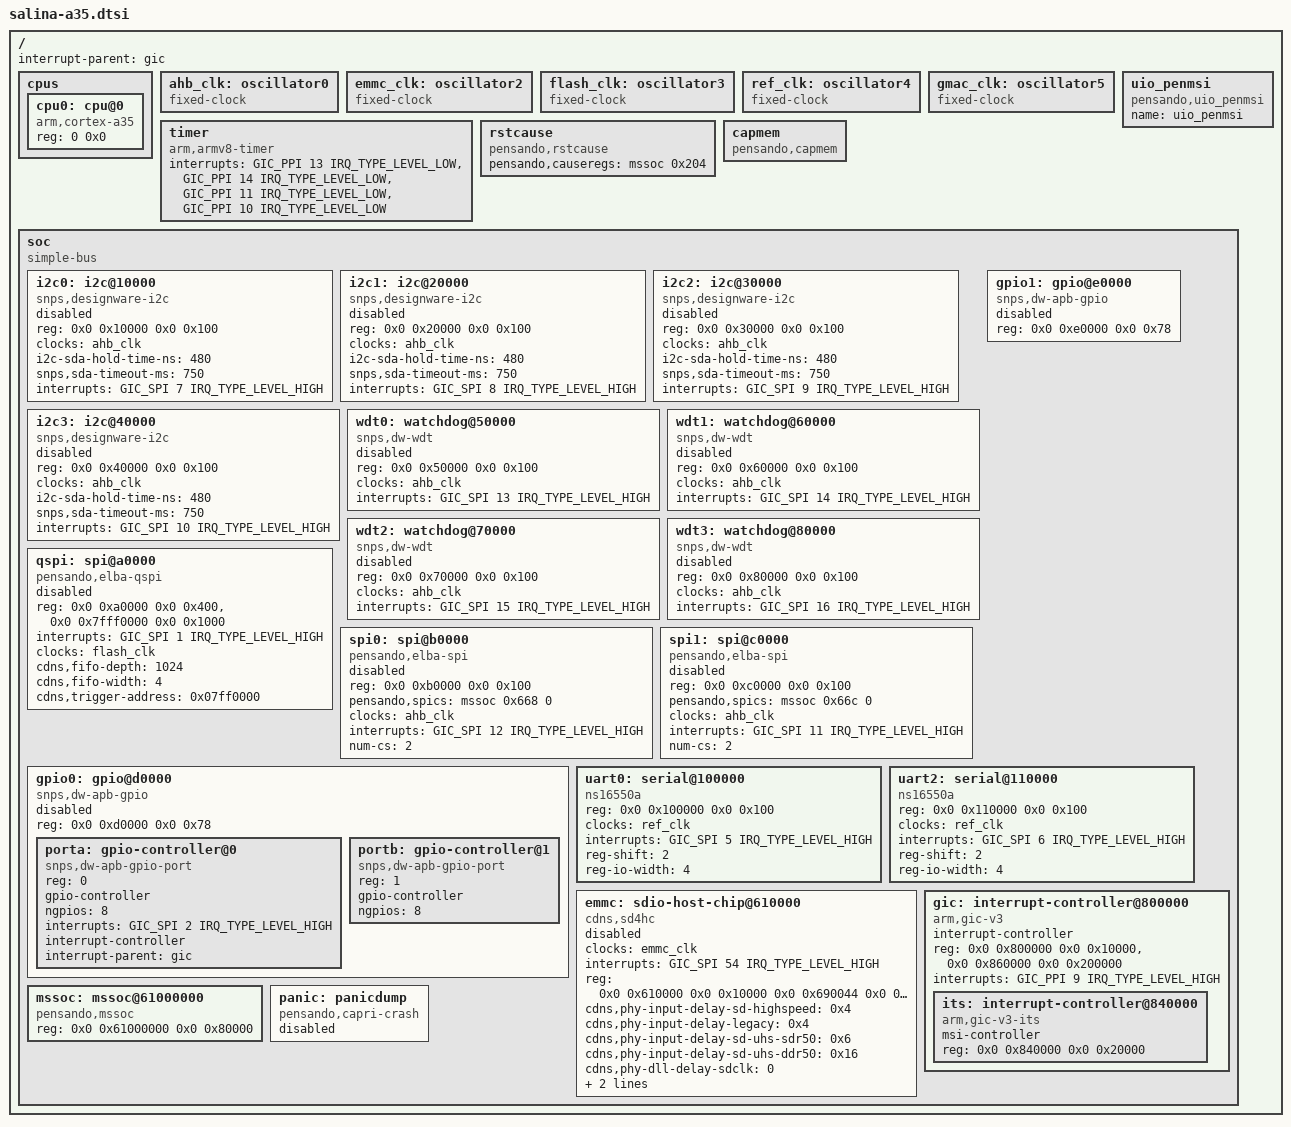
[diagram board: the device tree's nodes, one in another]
// SPDX-License-Identifier: (GPL-2.0-only or BSD-2-Clause)
/*
 * Copyright 2023-2024 Advanced Micro Devices, Inc.
 */

#include <dt-bindings/gpio/gpio.h>
#include "dt-bindings/interrupt-controller/arm-gic.h"
#include "dt-bindings/interrupt-controller/irq.h"

/ {
	interrupt-parent = <&gic>;
	#address-cells = <2>;
	#size-cells = <2>;

	cpus {
		#address-cells = <2>;
		#size-cells = <0>;

		cpu0: cpu@0 {
			device_type = "cpu";
			compatible = "arm,cortex-a35";
			reg = <0 0x0>;
		};
	};

	ahb_clk: oscillator0 {
		compatible = "fixed-clock";
		#clock-cells = <0>;
	};

	emmc_clk: oscillator2 {
		compatible = "fixed-clock";
		#clock-cells = <0>;
	};

	flash_clk: oscillator3 {
		compatible = "fixed-clock";
		#clock-cells = <0>;
	};

	ref_clk: oscillator4 {
		compatible = "fixed-clock";
		#clock-cells = <0>;
	};

	gmac_clk: oscillator5 {
		compatible = "fixed-clock";
		#clock-cells = <0>;
	};

	timer {
		compatible = "arm,armv8-timer";
		interrupts = <GIC_PPI 13 IRQ_TYPE_LEVEL_LOW>,
			     <GIC_PPI 14 IRQ_TYPE_LEVEL_LOW>,
			     <GIC_PPI 11 IRQ_TYPE_LEVEL_LOW>,
			     <GIC_PPI 10 IRQ_TYPE_LEVEL_LOW>;
	};

	/* Common UIO device for MSI drivers */
	uio_penmsi {
		compatible = "pensando,uio_penmsi";
		name = "uio_penmsi";
	};

	rstcause {
		compatible = "pensando,rstcause";
		pensando,causeregs = <&mssoc 0x204>;
	};

	capmem {
		compatible = "pensando,capmem";
	};

	soc: soc {
		compatible = "simple-bus";
		#address-cells = <2>;
		#size-cells = <2>;
		ranges;

		i2c0: i2c@10000 {
			compatible = "snps,designware-i2c";
			reg = <0x0 0x10000 0x0 0x100>;
			clocks = <&ahb_clk>;
			#address-cells = <1>;
			#size-cells = <0>;
			i2c-sda-hold-time-ns = <480>;
			snps,sda-timeout-ms = <750>;
			interrupts = <GIC_SPI 7 IRQ_TYPE_LEVEL_HIGH>;
			status = "disabled";
		};

		i2c1: i2c@20000 {
			compatible = "snps,designware-i2c";
			reg = <0x0 0x20000 0x0 0x100>;
			clocks = <&ahb_clk>;
			#address-cells = <1>;
			#size-cells = <0>;
			i2c-sda-hold-time-ns = <480>;
			snps,sda-timeout-ms = <750>;
			interrupts = <GIC_SPI 8 IRQ_TYPE_LEVEL_HIGH>;
			status = "disabled";
		};

		i2c2: i2c@30000 {
			compatible = "snps,designware-i2c";
			reg = <0x0 0x30000 0x0 0x100>;
			clocks = <&ahb_clk>;
			#address-cells = <1>;
			#size-cells = <0>;
			i2c-sda-hold-time-ns = <480>;
			snps,sda-timeout-ms = <750>;
			interrupts = <GIC_SPI 9 IRQ_TYPE_LEVEL_HIGH>;
			status = "disabled";
		};

		i2c3: i2c@40000 {
			compatible = "snps,designware-i2c";
			reg = <0x0 0x40000 0x0 0x100>;
			clocks = <&ahb_clk>;
			#address-cells = <1>;
			#size-cells = <0>;
			i2c-sda-hold-time-ns = <480>;
			snps,sda-timeout-ms = <750>;
			interrupts = <GIC_SPI 10 IRQ_TYPE_LEVEL_HIGH>;
			status = "disabled";
		};

		wdt0: watchdog@50000 {
			compatible = "snps,dw-wdt";
			reg = <0x0 0x50000 0x0 0x100>;
			clocks = <&ahb_clk>;
			interrupts = <GIC_SPI 13 IRQ_TYPE_LEVEL_HIGH>;
			status = "disabled";
		};

		wdt1: watchdog@60000 {
			compatible = "snps,dw-wdt";
			reg = <0x0 0x60000 0x0 0x100>;
			clocks = <&ahb_clk>;
			interrupts = <GIC_SPI 14 IRQ_TYPE_LEVEL_HIGH>;
			status = "disabled";
		};

		wdt2: watchdog@70000 {
			compatible = "snps,dw-wdt";
			reg = <0x0 0x70000 0x0 0x100>;
			clocks = <&ahb_clk>;
			interrupts = <GIC_SPI 15 IRQ_TYPE_LEVEL_HIGH>;
			status = "disabled";
		};

		wdt3: watchdog@80000 {
			compatible = "snps,dw-wdt";
			reg = <0x0 0x80000 0x0 0x100>;
			clocks = <&ahb_clk>;
			interrupts = <GIC_SPI 16 IRQ_TYPE_LEVEL_HIGH>;
			status = "disabled";
		};

		qspi: spi@a0000 {
			compatible = "pensando,elba-qspi";
			#address-cells = <1>;
			#size-cells = <0>;
			reg = <0x0 0xa0000 0x0 0x400>,
			      <0x0 0x7fff0000 0x0 0x1000>;
			interrupts = <GIC_SPI 1 IRQ_TYPE_LEVEL_HIGH>;
			clocks = <&flash_clk>;
			cdns,fifo-depth = <1024>;
			cdns,fifo-width = <4>;
			cdns,trigger-address = <0x07ff0000>;
			status = "disabled";
		};

		spi0: spi@b0000 {
			compatible = "pensando,elba-spi";
			reg = <0x0 0xb0000 0x0 0x100>;
			pensando,spics = <&mssoc 0x668 0>;
			clocks = <&ahb_clk>;
			interrupts = <GIC_SPI 12 IRQ_TYPE_LEVEL_HIGH>;
			#address-cells = <1>;
			#size-cells = <0>;
			num-cs = <2>;
			status = "disabled";
		};

		spi1: spi@c0000 {
			compatible = "pensando,elba-spi";
			reg = <0x0 0xc0000 0x0 0x100>;
			pensando,spics = <&mssoc 0x66c 0>;
			clocks = <&ahb_clk>;
			interrupts = <GIC_SPI 11 IRQ_TYPE_LEVEL_HIGH>;
			#address-cells = <1>;
			#size-cells = <0>;
			num-cs = <2>;
			status = "disabled";
		};

		gpio0: gpio@d0000 {
			#address-cells = <1>;
			#size-cells = <0>;
			compatible = "snps,dw-apb-gpio";
			reg = <0x0 0xd0000 0x0 0x78>;
			status = "disabled";

			porta: gpio-controller@0 {
				compatible = "snps,dw-apb-gpio-port";
				reg = <0>;
				gpio-controller;
				#gpio-cells = <2>;
				ngpios = <8>;
				interrupts = <GIC_SPI 2 IRQ_TYPE_LEVEL_HIGH>;
				interrupt-controller;
				interrupt-parent = <&gic>;
				#interrupt-cells = <2>;
			};
			portb: gpio-controller@1 {
				compatible = "snps,dw-apb-gpio-port";
				reg = <1>;
				gpio-controller;
				#gpio-cells = <2>;
				ngpios = <8>;
			};
		};

		gpio1: gpio@e0000 {
			#address-cells = <1>;
			#size-cells = <0>;
			compatible = "snps,dw-apb-gpio";
			reg = <0x0 0xe0000 0x0 0x78>;
			status = "disabled";
		};

		uart0: serial@100000 {
			device_type = "serial";
			compatible = "ns16550a";
			reg = <0x0 0x100000 0x0 0x100>;
			clocks = <&ref_clk>;
			interrupts = <GIC_SPI 5 IRQ_TYPE_LEVEL_HIGH>;
			reg-shift = <2>;
			reg-io-width = <4>;
		};

		uart2: serial@110000 {
			device_type = "serial";
			compatible = "ns16550a";
			reg = <0x0 0x110000 0x0 0x100>;
			clocks = <&ref_clk>;
			interrupts = <GIC_SPI 6 IRQ_TYPE_LEVEL_HIGH>;
			reg-shift = <2>;
			reg-io-width = <4>;
		};

		emmc: sdio-host-chip@610000 {
			compatible = "cdns,sd4hc";
			clocks = <&emmc_clk>;
			interrupts = <GIC_SPI 54 IRQ_TYPE_LEVEL_HIGH>;
			reg = <0x0 0x610000 0x0 0x10000
			       0x0 0x690044 0x0 0x4>;
			cdns,phy-input-delay-sd-highspeed = <0x4>;
			cdns,phy-input-delay-legacy = <0x4>;
			cdns,phy-input-delay-sd-uhs-sdr50 = <0x6>;
			cdns,phy-input-delay-sd-uhs-ddr50 = <0x16>;
			cdns,phy-dll-delay-sdclk = <0>;
			cdns,phy-dll-delay-sdclk-hsmmc = <0>;
			cdns,mmc-ddr-1_8v;
			status = "disabled";
		};

		gic: interrupt-controller@800000 {
			compatible = "arm,gic-v3";
			#interrupt-cells = <3>;
			#address-cells = <2>;
			#size-cells = <2>;
			ranges;
			interrupt-controller;
			reg = <0x0 0x800000 0x0 0x10000>,	/* GICD */
			      <0x0 0x860000 0x0 0x200000>;	/* GICR */
			interrupts = <GIC_PPI 9 IRQ_TYPE_LEVEL_HIGH>;

			its: interrupt-controller@840000 {
				compatible = "arm,gic-v3-its";
				msi-controller;
				#msi-cells = <1>;
				reg = <0x0 0x840000 0x0 0x20000>;
			};
		};

		mssoc: mssoc@61000000 {
			compatible = "pensando,mssoc", "syscon";
			reg = <0x0 0x61000000 0x0 0x80000>;
		};

		panic: panicdump {
			compatible = "pensando,capri-crash";
			status = "disabled";
		};
	};
};
